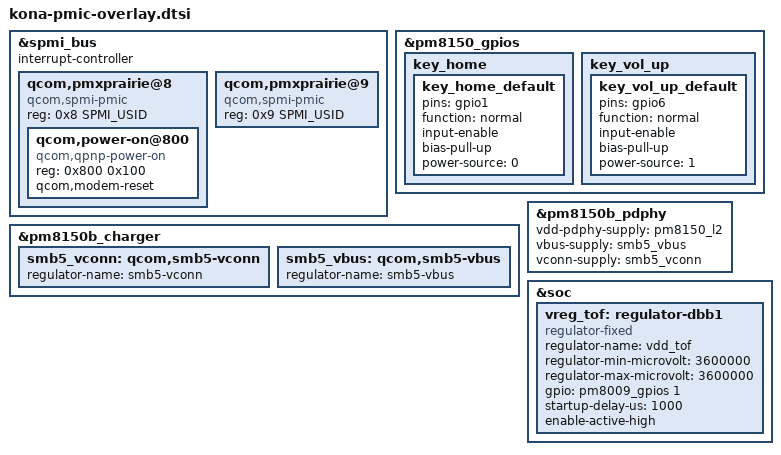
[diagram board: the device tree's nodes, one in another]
// SPDX-License-Identifier: GPL-2.0-only
/* Copyright (c) 2018-2019, The Linux Foundation. All rights reserved. */

#include <dt-bindings/gpio/gpio.h>
#include <dt-bindings/pinctrl/qcom,pmic-gpio.h>

#include "pm8150.dtsi"
#include "pm8150b.dtsi"
#include "pm8150l.dtsi"
#include "pm8009.dtsi"

&spmi_bus {
	#address-cells = <2>;
	#size-cells = <0>;
	interrupt-controller;
	#interrupt-cells = <4>;

	qcom,pmxprairie@8 {
		compatible = "qcom,spmi-pmic";
		reg = <0x8 SPMI_USID>;
		#address-cells = <2>;
		#size-cells = <0>;

		qcom,power-on@800 {
			compatible = "qcom,qpnp-power-on";
			reg = <0x800 0x100>;
			qcom,modem-reset;
		};
	};

	qcom,pmxprairie@9 {
		compatible ="qcom,spmi-pmic";
		reg = <0x9 SPMI_USID>;
		#address-cells = <2>;
		#size-cells = <0>;
	};
};

&pm8150_gpios {
	key_home {
		key_home_default: key_home_default {
			pins = "gpio1";
			function = "normal";
			input-enable;
			bias-pull-up;
			power-source = <0>;
		};
	};

	key_vol_up {
		key_vol_up_default: key_vol_up_default {
			pins = "gpio6";
			function = "normal";
			input-enable;
			bias-pull-up;
			power-source = <1>;
		};
	};
};

&pm8150b_charger {
	smb5_vconn: qcom,smb5-vconn {
		regulator-name = "smb5-vconn";
	};

	smb5_vbus: qcom,smb5-vbus {
		regulator-name = "smb5-vbus";
	};
};

&pm8150b_pdphy {
	vdd-pdphy-supply = <&pm8150_l2>;
	vbus-supply = <&smb5_vbus>;
	vconn-supply = <&smb5_vconn>;
};

&soc {
	vreg_tof: regulator-dbb1 {
		compatible = "regulator-fixed";
		regulator-name = "vdd_tof";
		regulator-min-microvolt = <3600000>;
		regulator-max-microvolt = <3600000>;
		gpio = <&pm8009_gpios 1 GPIO_ACTIVE_HIGH>;
		startup-delay-us = <1000>;
		enable-active-high;
	};
};
